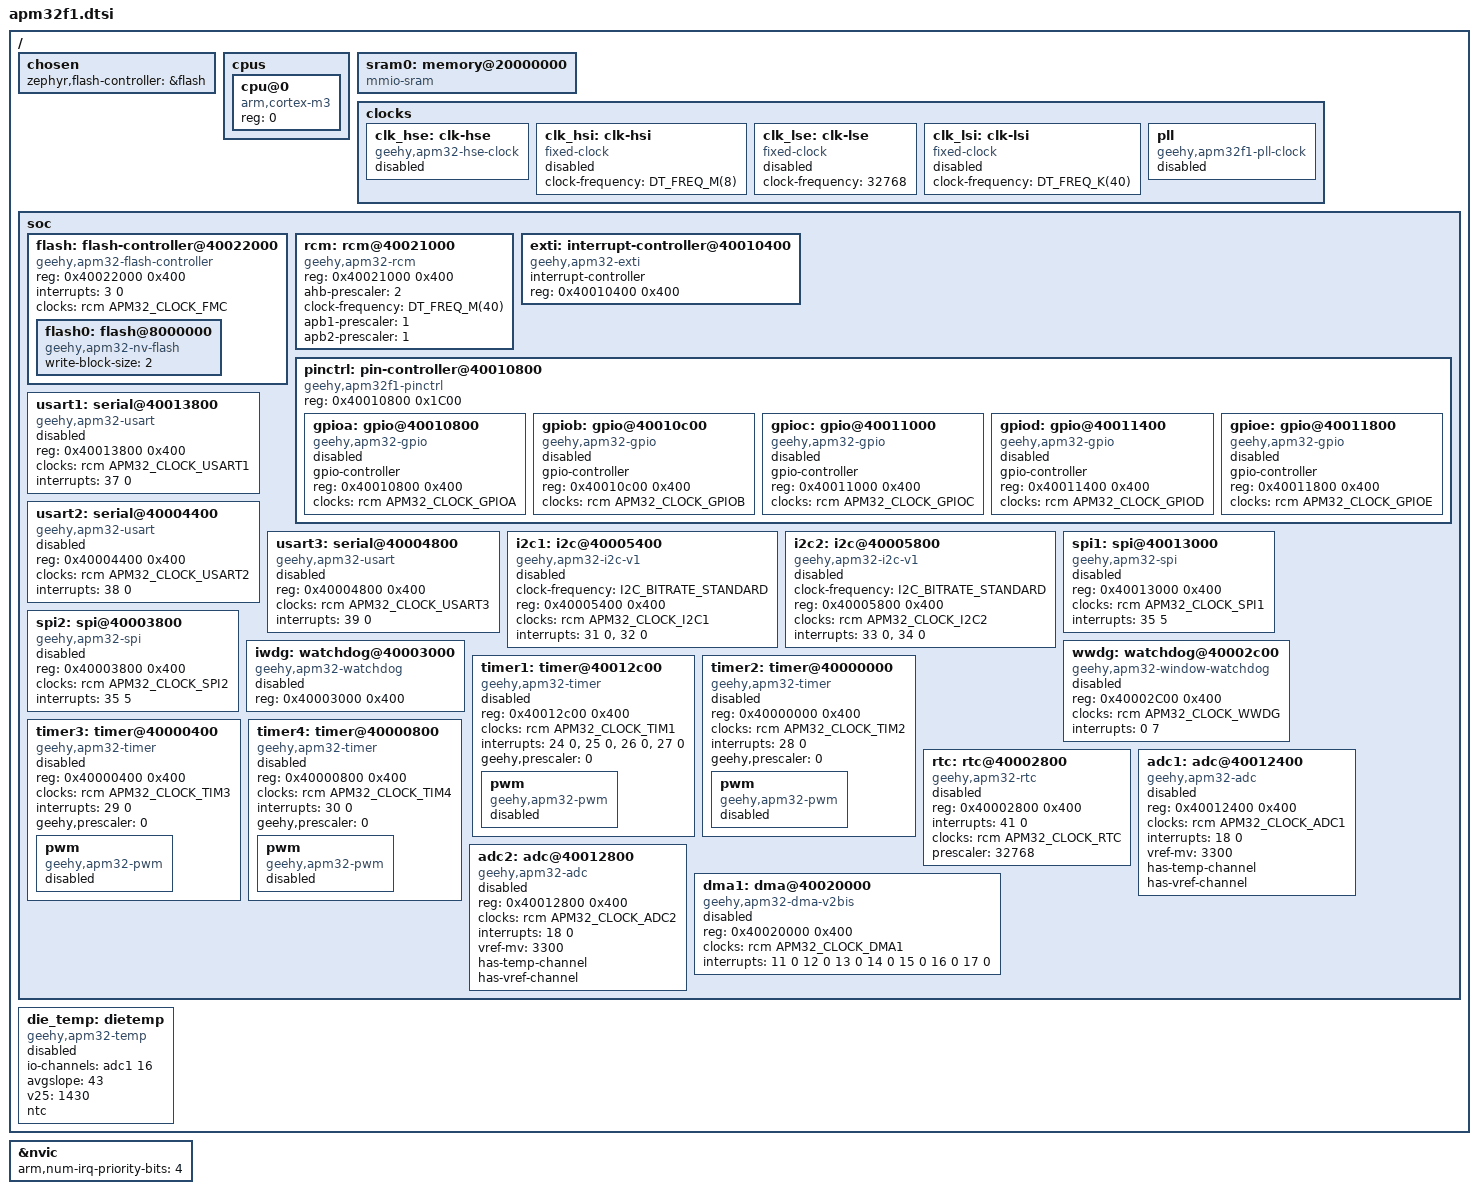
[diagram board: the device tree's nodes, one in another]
/*
 * Copyright (c) 2023, Quincy.W <wangqyfm@foxmail.com>
 * SPDX-License-Identifier: Apache-2.0
 */

#include <arm/armv7-m.dtsi>
#include <zephyr/dt-bindings/clock/apm32_clock_f1.h>
#include <zephyr/dt-bindings/i2c/i2c.h>
#include <zephyr/dt-bindings/gpio/gpio.h>
#include <zephyr/dt-bindings/pwm/pwm.h>
/* #include <zephyr/dt-bindings/pwm/apm32_pwm.h> */
#include <freq.h>

/ {
	chosen {
		zephyr,flash-controller = &flash;
	};

	cpus {
		#address-cells = <1>;
		#size-cells = <0>;

		cpu@0 {
			device_type = "cpu";
			compatible = "arm,cortex-m3";
			reg = <0>;
		};
	};

	sram0: memory@20000000 {
		compatible = "mmio-sram";
	};

	clocks {
		clk_hse: clk-hse {
			#clock-cells = <0>;
			compatible = "geehy,apm32-hse-clock";
			status = "disabled";
		};

		clk_hsi: clk-hsi {
			#clock-cells = <0>;
			compatible = "fixed-clock";
			clock-frequency = <DT_FREQ_M(8)>;
			status = "disabled";
		};

		clk_lse: clk-lse {
			#clock-cells = <0>;
			compatible = "fixed-clock";
			clock-frequency = <32768>;
			status = "disabled";
		};

		clk_lsi: clk-lsi {
			#clock-cells = <0>;
			compatible = "fixed-clock";
			clock-frequency = <DT_FREQ_K(40)>;
			status = "disabled";
		};

		pll: pll {
			#clock-cells = <0>;
			compatible = "geehy,apm32f1-pll-clock";
			status = "disabled";
		};
	};

	soc {

		flash: flash-controller@40022000 {
			compatible = "geehy,apm32-flash-controller", "geehy,apm32f1-flash-controller";
			reg = <0x40022000 0x400>;
			interrupts = <3 0>;
			clocks = <&rcm APM32_CLOCK_FMC>;

			#address-cells = <1>;
			#size-cells = <1>;

			flash0: flash@8000000 {
				compatible = "geehy,apm32-nv-flash", "soc-nv-flash";

				write-block-size = <2>;
			};
		};

		rcm: rcm@40021000 {
			compatible = "geehy,apm32-rcm";
			#clock-cells = <1>;
			reg = <0x40021000 0x400>;
            ahb-prescaler = <2>;
            clock-frequency = <DT_FREQ_M(40)>;
            apb1-prescaler = <1>;
            apb2-prescaler = <1>;
		};

		exti: interrupt-controller@40010400 {
			compatible = "geehy,apm32-exti";
			interrupt-controller;
			#interrupt-cells = <1>;
			reg = <0x40010400 0x400>;
		};

		pinctrl: pin-controller@40010800 {
			compatible = "geehy,apm32f1-pinctrl";
			#address-cells = <1>;
			#size-cells = <1>;
			reg = <0x40010800 0x1C00>;

			gpioa: gpio@40010800 {
				compatible = "geehy,apm32-gpio";
				gpio-controller;
				#gpio-cells = <2>;
				reg = <0x40010800 0x400>;
				clocks = <&rcm APM32_CLOCK_GPIOA>;
				status = "disabled";
			};
			
			gpiob: gpio@40010c00 {
				compatible = "geehy,apm32-gpio";
				gpio-controller;
				#gpio-cells = <2>;
				reg = <0x40010c00 0x400>;
				clocks = <&rcm APM32_CLOCK_GPIOB>;
				status = "disabled";
			};

			gpioc: gpio@40011000 {
				compatible = "geehy,apm32-gpio";
				gpio-controller;
				#gpio-cells = <2>;
				reg = <0x40011000 0x400>;
				clocks = <&rcm APM32_CLOCK_GPIOC>;
				status = "disabled";
			};

			gpiod: gpio@40011400 {
				compatible = "geehy,apm32-gpio";
				gpio-controller;
				#gpio-cells = <2>;
				reg = <0x40011400 0x400>;
				clocks = <&rcm APM32_CLOCK_GPIOD>;
				status = "disabled";
			};

			gpioe: gpio@40011800 {
				compatible = "geehy,apm32-gpio";
				gpio-controller;
				#gpio-cells = <2>;
				reg = <0x40011800 0x400>;
				clocks = <&rcm APM32_CLOCK_GPIOE>;
				status = "disabled";
			};
		};

		usart1: serial@40013800 {
			compatible = "geehy,apm32-usart", "geehy,apm32-uart";
			reg = <0x40013800 0x400>;
			clocks = <&rcm APM32_CLOCK_USART1>;
			interrupts = <37 0>;
			status = "disabled";
		};

		usart2: serial@40004400 {
			compatible = "geehy,apm32-usart", "geehy,apm32-uart";
			reg = <0x40004400 0x400>;
			clocks = <&rcm APM32_CLOCK_USART2>;
			interrupts = <38 0>;
			status = "disabled";
		};

		usart3: serial@40004800 {
			compatible = "geehy,apm32-usart", "geehy,apm32-uart";
			reg = <0x40004800 0x400>;
			clocks = <&rcm APM32_CLOCK_USART3>;
			interrupts = <39 0>;
			status = "disabled";
		};

		i2c1: i2c@40005400 {
			compatible = "geehy,apm32-i2c-v1";
			clock-frequency = <I2C_BITRATE_STANDARD>;
			#address-cells = <1>;
			#size-cells = <0>;
			reg = <0x40005400 0x400>;
			clocks = <&rcm APM32_CLOCK_I2C1>;
			interrupts = <31 0>, <32 0>;
			interrupt-names = "event", "error";
			status = "disabled";
		};

		i2c2: i2c@40005800 {
			compatible = "geehy,apm32-i2c-v1";
			clock-frequency = <I2C_BITRATE_STANDARD>;
			#address-cells = <1>;
			#size-cells = <0>;
			reg = <0x40005800 0x400>;
			clocks = <&rcm APM32_CLOCK_I2C2>;
			interrupts = <33 0>, <34 0>;
			interrupt-names = "event", "error";
			status = "disabled";
		};

		spi1: spi@40013000 {
			compatible = "geehy,apm32-spi";
			#address-cells = <1>;
			#size-cells = <0>;
			reg = <0x40013000 0x400>;
			clocks = <&rcm APM32_CLOCK_SPI1>;
			interrupts = <35 5>;
			status = "disabled";
		};

		spi2: spi@40003800 {
			compatible = "geehy,apm32-spi";
			#address-cells = <1>;
			#size-cells = <0>;
			reg = <0x40003800 0x400>;
			clocks = <&rcm APM32_CLOCK_SPI2>;
			interrupts = <35 5>;
			status = "disabled";
		};

		iwdg: watchdog@40003000 {
			compatible = "geehy,apm32-watchdog";
			reg = <0x40003000 0x400>;
			status = "disabled";
		};

		wwdg: watchdog@40002c00 {
			compatible = "geehy,apm32-window-watchdog";
			reg = <0x40002C00 0x400>;
			clocks = <&rcm APM32_CLOCK_WWDG>;
			interrupts = <0 7>;
			status = "disabled";
		};

		timer1: timer@40012c00 {
			compatible = "geehy,apm32-timer";
			reg = <0x40012c00 0x400>;
			clocks = <&rcm APM32_CLOCK_TIM1>;
			interrupts = <24 0>, <25 0>, <26 0>, <27 0>;
			interrupt-names = "brk", "up", "trgcom", "cc";
			geehy,prescaler = <0>;
			status = "disabled";

			pwm {
				compatible = "geehy,apm32-pwm";
				status = "disabled";
				#pwm-cells = <3>;
			};
		};

		timer2: timer@40000000 {
			compatible = "geehy,apm32-timer";
			reg = <0x40000000 0x400>;
			clocks = <&rcm APM32_CLOCK_TIM2>;
			interrupts = <28 0>;
			interrupt-names = "global";
			geehy,prescaler = <0>;
			status = "disabled";

			pwm {
				compatible = "geehy,apm32-pwm";
				status = "disabled";
				#pwm-cells = <3>;
			};
		};

		timer3: timer@40000400 {
			compatible = "geehy,apm32-timer";
			reg = <0x40000400 0x400>;
			clocks = <&rcm APM32_CLOCK_TIM3>;
			interrupts = <29 0>;
			interrupt-names = "global";
			geehy,prescaler = <0>;
			status = "disabled";

			pwm {
				compatible = "geehy,apm32-pwm";
				status = "disabled";
				#pwm-cells = <3>;
			};
		};

		timer4: timer@40000800 {
			compatible = "geehy,apm32-timer";
			reg = <0x40000800 0x400>;
			clocks = <&rcm APM32_CLOCK_TIM4>;
			interrupts = <30 0>;
			interrupt-names = "global";
			geehy,prescaler = <0>;
			status = "disabled";

			pwm {
				compatible = "geehy,apm32-pwm";
				status = "disabled";
				#pwm-cells = <3>;
			};
		};

		rtc: rtc@40002800 {
			compatible = "geehy,apm32-rtc";
			reg = <0x40002800 0x400>;
			interrupts = <41 0>;
			clocks = <&rcm APM32_CLOCK_RTC>;
			prescaler = <32768>;
			status = "disabled";
		};

		adc1: adc@40012400 {
			compatible = "geehy,apm32-adc";
			reg = <0x40012400 0x400>;
			clocks = <&rcm APM32_CLOCK_ADC1>;
			interrupts = <18 0>;
			status = "disabled";
			vref-mv = <3300>;
			#io-channel-cells = <1>;
			has-temp-channel;
			has-vref-channel;
		};

		adc2: adc@40012800 {
			compatible = "geehy,apm32-adc";
			reg = <0x40012800 0x400>;
			clocks = <&rcm APM32_CLOCK_ADC2>;
			interrupts = <18 0>;
			status = "disabled";
			vref-mv = <3300>;
			#io-channel-cells = <1>;
			has-temp-channel;
			has-vref-channel;
		};

		dma1: dma@40020000 {
			compatible = "geehy,apm32-dma-v2bis";
			#dma-cells = <2>;
			reg = <0x40020000 0x400>;
			clocks = <&rcm APM32_CLOCK_DMA1>;
			interrupts = <11 0 12 0 13 0 14 0 15 0 16 0 17 0>;
			status = "disabled";
		};
	};

	die_temp: dietemp {
		compatible = "geehy,apm32-temp";
		io-channels = <&adc1 16>;
		status = "disabled";
		avgslope = <43>;
		v25 = <1430>;
		ntc;
	};
};

&nvic {
	arm,num-irq-priority-bits = <4>;
};
